# HDSC_HC32L156KX register map
Vendor: HDSC Co.Ltd; Series: ARMCM0P; File version: 1.2
CPU: CM0 r0p0, little endian, no MPU, no FPU, 3 interrupt priority bits
Registers are 8-bit, read-write, reset 0x0 unless marked. A register's access mark holds for its fields unless they carry their own. Offsets are from the block's base; [hi:lo] are bit positions; {n}, {i} and the like mark numbered series.

## DTIM1 — desc DTIM
Base 0x40015000
Same registers: DTIM2 0x40015020
0x00 TIMERLOAD 32-bit
0x04 TIMERVALUE 32-bit ro reset 0xFFFFFFFF
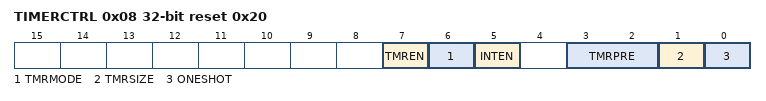
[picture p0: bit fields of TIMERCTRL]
0x08 TIMERCTRL 32-bit reset 0x20
  [7] TMREN, [6] TMRMODE, [5] INTEN, [3:2] TMRPRE, [1] TMRSIZE, [0] ONESHOT
0x0C TIMERINTCLR 32-bit wo reset 0xFFFFFFFF
0x10 TIMERRIS 32-bit ro
  [0] TMRINTST
0x14 TIMERMIS 32-bit ro
  [0] TMRMINTST
0x18 TIMERBGLOAD 32-bit

## EXTINT
Base 0x40030000
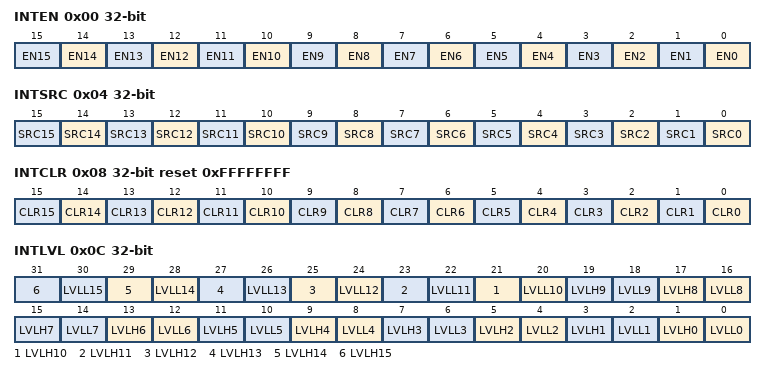
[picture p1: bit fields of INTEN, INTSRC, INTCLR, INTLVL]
0x00 INTEN 32-bit
  [n] EN{n} (n=0..15)
0x04 INTSRC 32-bit ro
  [n] SRC{n} (n=0..15)
0x08 INTCLR 32-bit reset 0xFFFFFFFF
  [n] CLR{n} (n=0..15)
0x0C INTLVL 32-bit
  [2n+1] LVLH{n} (n=0..15), [2n] LVLL{n} (n=0..15)
0x14 NMISRC 16-bit ro
  [0] SRC
0x18 NMICLR 16-bit reset 0x1
  [0] CLR

## FASTIO
Base 0xF8000000
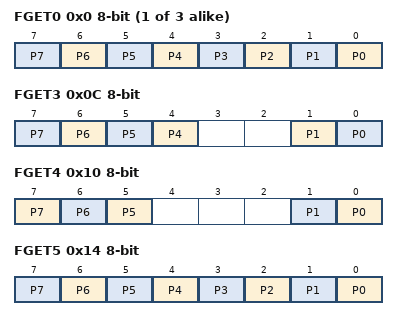
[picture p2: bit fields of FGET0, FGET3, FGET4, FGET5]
{0x0+4i} FGET{i} ro (i=0..2)
  [n] P{n} (n=0..7)
0x0C FGET3 ro
  [n] P{n} (n=4..7), [1] P1, [0] P0
0x10 FGET4 ro
  [7] P7, [6] P6, [5] P5, [1] P1, [0] P0
0x14 FGET5 ro
  [n] P{n} (n=0..7)
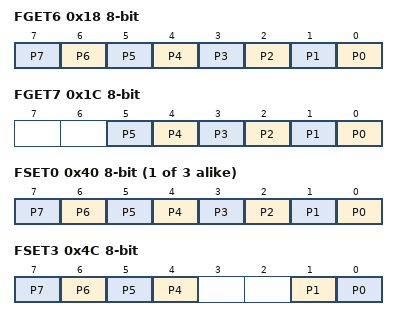
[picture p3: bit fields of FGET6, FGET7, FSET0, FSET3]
0x18 FGET6 ro
  [n] P{n} (n=0..7)
0x1C FGET7 ro (reset mask 0x1F)
  [n] P{n} (n=0..5)
{0x40+4i} FSET{i} (i=0..2)
  [n] P{n} (n=0..7)
0x4C FSET3
  [n] P{n} (n=4..7), [1] P1, [0] P0
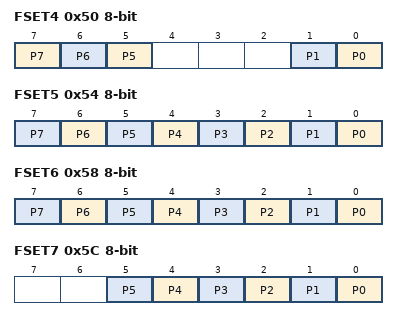
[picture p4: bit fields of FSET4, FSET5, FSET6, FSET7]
0x50 FSET4
  [7] P7, [6] P6, [5] P5, [1] P1, [0] P0
0x54 FSET5
  [n] P{n} (n=0..7)
0x58 FSET6
  [n] P{n} (n=0..7)
0x5C FSET7 (reset mask 0x1F)
  [n] P{n} (n=0..5)

## FLASH
Base 0x40000000
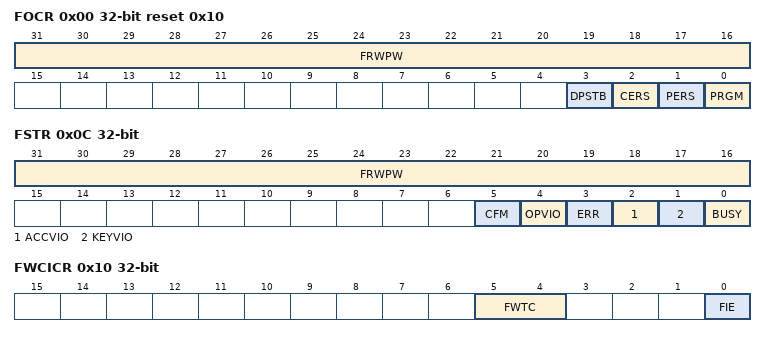
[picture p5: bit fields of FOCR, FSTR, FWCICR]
0x00 FOCR 32-bit reset 0x10
  [31:16] FRWPW, [3] DPSTB, [2] CERS, [1] PERS, [0] PRGM
0x04 FLCR0 32-bit reset 0xFFFFFFFF
  [31:0] LOCK2K
0x08 FLCR1 32-bit reset 0xFFFFFFFF
  [31:0] LOCK2K
0x0C FSTR 32-bit
  [31:16] FRWPW, [5] CFM, [4] OPVIO, [3] ERR, [2] ACCVIO, [1] KEYVIO, [0] BUSY ro
0x10 FWCICR 32-bit
  [5:4] FWTC, [0] FIE
{0x14+4i} FUDR{i} 32-bit ro (i=0..3)
  [31:0] UD{i}
0x24 TNVS reset 0x18
0x28 TPROG reset 0x18
0x2C TPGS reset 0x18
0x30 TRCVPGM reset 0x18
0x34 TRCVPERS reset 0x19
0x38 TRCVCERS reset 0x7
0x3C TPERS reset 0x10
0x40 TCERS reset 0x20

## GPIO
Base 0x40033000
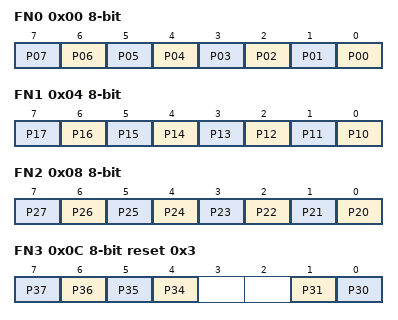
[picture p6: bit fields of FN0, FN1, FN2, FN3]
0x00 FN0
  [n] P{n:02} (n=0..7)
0x04 FN1
  [n-10] P{n} (n=10..17)
0x08 FN2
  [n-20] P{n} (n=20..27)
0x0C FN3 reset 0x3
  [n-30] P{n} (n=34..37), [1] P31, [0] P30
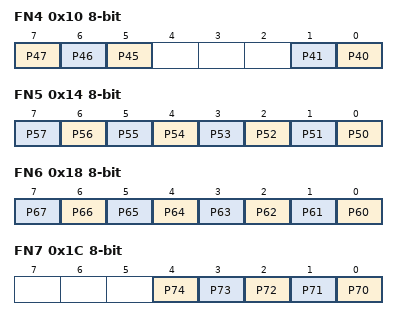
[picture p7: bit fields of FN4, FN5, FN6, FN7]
0x10 FN4
  [7] P47, [6] P46, [5] P45, [1] P41, [0] P40
0x14 FN5
  [n-50] P{n} (n=50..57)
0x18 FN6
  [n-60] P{n} (n=60..67)
0x1C FN7
  [n-70] P{n} (n=70..74)
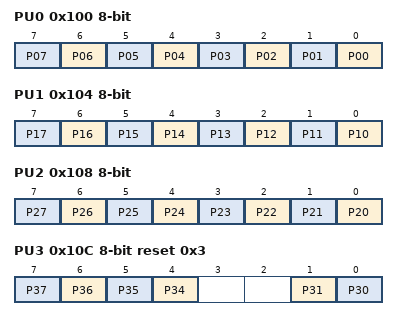
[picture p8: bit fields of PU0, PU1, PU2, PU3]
0x100 PU0
  [n] P{n:02} (n=0..7)
0x104 PU1
  [n-10] P{n} (n=10..17)
0x108 PU2
  [n-20] P{n} (n=20..27)
0x10C PU3 reset 0x3
  [n-30] P{n} (n=34..37), [1] P31, [0] P30
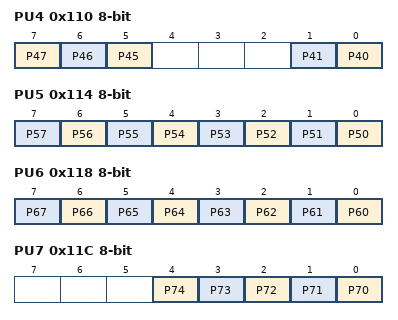
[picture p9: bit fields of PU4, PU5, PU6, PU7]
0x110 PU4
  [7] P47, [6] P46, [5] P45, [1] P41, [0] P40
0x114 PU5
  [n-50] P{n} (n=50..57)
0x118 PU6
  [n-60] P{n} (n=60..67)
0x11C PU7
  [n-70] P{n} (n=70..74)
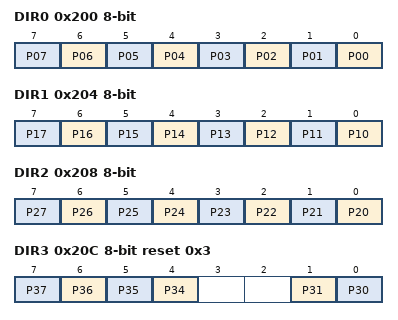
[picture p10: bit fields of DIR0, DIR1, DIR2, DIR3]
0x200 DIR0
  [n] P{n:02} (n=0..7)
0x204 DIR1
  [n-10] P{n} (n=10..17)
0x208 DIR2
  [n-20] P{n} (n=20..27)
0x20C DIR3 reset 0x3
  [n-30] P{n} (n=34..37), [1] P31, [0] P30
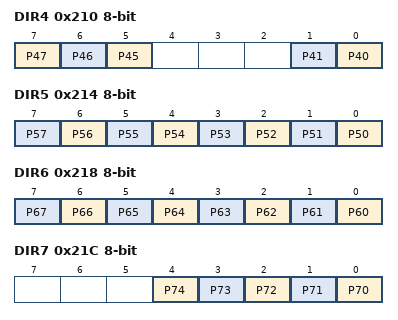
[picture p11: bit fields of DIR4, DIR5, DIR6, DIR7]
0x210 DIR4
  [7] P47, [6] P46, [5] P45, [1] P41, [0] P40
0x214 DIR5
  [n-50] P{n} (n=50..57)
0x218 DIR6
  [n-60] P{n} (n=60..67)
0x21C DIR7
  [n-70] P{n} (n=70..74)
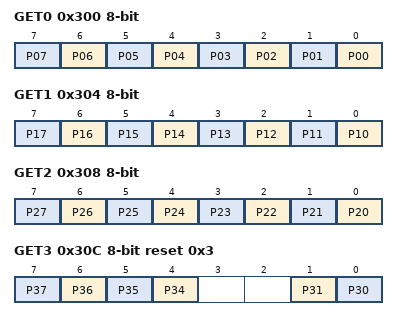
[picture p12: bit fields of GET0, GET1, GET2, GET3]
0x300 GET0
  [n] P{n:02} (n=0..7)
0x304 GET1
  [n-10] P{n} (n=10..17)
0x308 GET2
  [n-20] P{n} (n=20..27)
0x30C GET3 reset 0x3
  [n-30] P{n} (n=34..37), [1] P31, [0] P30
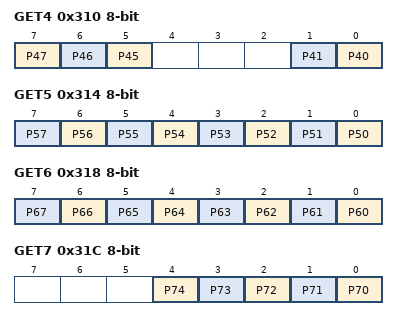
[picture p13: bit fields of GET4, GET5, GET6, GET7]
0x310 GET4
  [7] P47, [6] P46, [5] P45, [1] P41, [0] P40
0x314 GET5
  [n-50] P{n} (n=50..57)
0x318 GET6
  [n-60] P{n} (n=60..67)
0x31C GET7
  [n-70] P{n} (n=70..74)
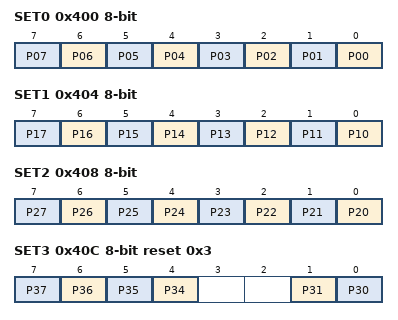
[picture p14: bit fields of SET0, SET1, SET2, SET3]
0x400 SET0
  [n] P{n:02} (n=0..7)
0x404 SET1
  [n-10] P{n} (n=10..17)
0x408 SET2
  [n-20] P{n} (n=20..27)
0x40C SET3 reset 0x3
  [n-30] P{n} (n=34..37), [1] P31, [0] P30
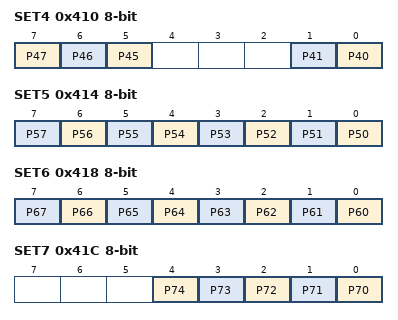
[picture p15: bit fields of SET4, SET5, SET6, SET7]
0x410 SET4
  [7] P47, [6] P46, [5] P45, [1] P41, [0] P40
0x414 SET5
  [n-50] P{n} (n=50..57)
0x418 SET6
  [n-60] P{n} (n=60..67)
0x41C SET7
  [n-70] P{n} (n=70..74)
0x500 ANALOG 16-bit
  [n] ADE{n:02} (n=0..15)
0x580 SPS reset 0x5
  [3:2] MAINCS, [1:0] SUBCS
0x600 FN_SEL00 16-bit reset 0x100
  [8] SWDEN, [7:6] SUBOUTE, [5:4] RTCCOE, [2:1] CROUTE, [0] NMIS
0x608 FN_SEL02 32-bit
  [29:28] TIOB3S, [8n+3:8n+2] TIOA{n}E (n=0..3), [25:24] TIOA3S, [22:20] TIOB2S, [13:12] TIOB1S, [9:8] TIOA1S, [6:4] TIOB0S
0x60C FN_SEL03 32-bit
  [8n-27:8n-28] TIOB{n}S (n=4..7), [8n-29:8n-30] TIOA{n}E (n=4..7), [25:24] TIOA7S, [9:8] TIOA5S
0x610 FN_SEL04 32-bit
  [2n+1:2n] EINT{n:02}S (n=0..15)
0x614 FN_SEL05 32-bit
  [27:26] SCS10B, [25:24] SCK1B, [23:22] SOT1B, [21:20] SIN1S, [19:18] CTS1S, [17:16] RTS1E, [9:8] SCK0B, [7:6] SOT0B, [5:4] SIN0S
0x618 FN_SEL06 32-bit
  [15:14] SCS22E, [13:12] SCS21E, [11:10] SCS20B, [9:8] SCK2B, [7:6] SOT2B, [5:4] SIN2S
0x61C FN_SEL07 32-bit
  [27:26] SCS50B, [25:24] SCK5B, [23:22] SOT5B, [21:20] SIN5S, [13:12] SCS41E, [11:10] SCS40B, [9:8] SCK4B, [7:6] SOT4B, [5:4] SIN4S, [3:2] CTS4S, [1:0] RTS4E
0x620 FN_SEL08 32-bit
  [15:14] SCS62E, [13:12] SCS61E, [11:10] SCS60B, [9:8] SCK6B, [7:6] SOT6B, [5:4] SIN6S, [3:2] CTS6S, [1:0] RTS6E
0x624 FN_SEL09 16-bit
  [13:12] ICRSTE, [11:10] ICIOB, [9:8] ICCKE, [5:4] BZOE, [1:0] VCOE
0x700 ODR0
  [n] P{n:02} (n=0..7)
0x704 ODR1
  [n-10] P{n} (n=10..17)
0x708 ODR2
  [n-20] P{n} (n=20..27)
0x70C ODR3 reset 0x3
  [n-30] P{n} (n=34..37), [1] P31, [0] P30
0x710 ODR4
  [7] P47, [6] P46, [5] P45, [1] P41, [0] P40
0x714 ODR5
  [n-50] P{n} (n=50..57)
0x718 ODR6
  [n-60] P{n} (n=60..67)
0x71C ODR7
  [n-70] P{n} (n=70..74)
